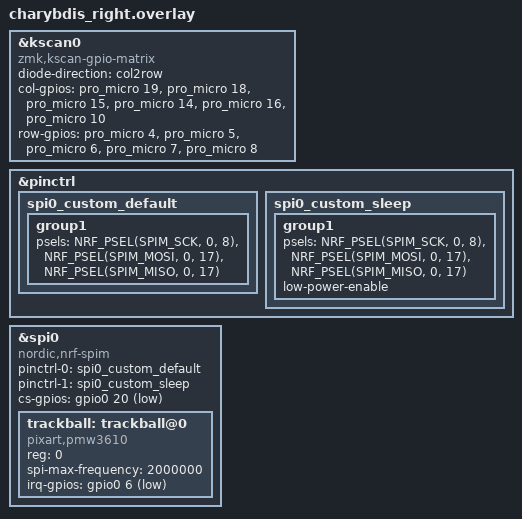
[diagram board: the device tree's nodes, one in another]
#include <dt-bindings/zmk/matrix_transform.h>
#include <dt-bindings/pinctrl/nrf-pinctrl.h>

/* [1] 키 배선 수정 (성공했으니 유지) */
&kscan0 {
    compatible = "zmk,kscan-gpio-matrix";
    diode-direction = "col2row";
    col-gpios
        = <&pro_micro 19 GPIO_ACTIVE_HIGH>
        , <&pro_micro 18 GPIO_ACTIVE_HIGH>
        , <&pro_micro 15 GPIO_ACTIVE_HIGH>
        , <&pro_micro 14 GPIO_ACTIVE_HIGH>
        , <&pro_micro 16 GPIO_ACTIVE_HIGH>
        , <&pro_micro 10 GPIO_ACTIVE_HIGH>;
    row-gpios
        = <&pro_micro 4 (GPIO_ACTIVE_HIGH | GPIO_PULL_DOWN)>
        , <&pro_micro 5 (GPIO_ACTIVE_HIGH | GPIO_PULL_DOWN)>
        , <&pro_micro 6 (GPIO_ACTIVE_HIGH | GPIO_PULL_DOWN)>
        , <&pro_micro 7 (GPIO_ACTIVE_HIGH | GPIO_PULL_DOWN)>
        , <&pro_micro 8 (GPIO_ACTIVE_HIGH | GPIO_PULL_DOWN)>;
};

/* [2] 트랙볼 충돌 방지: 기존 설정을 삭제합니다 */
/delete-node/ &trackball; 

/* [3] 트랙볼 핀 설정 (이름을 Custom으로 변경하여 강제 적용) */
&pinctrl {
    spi0_custom_default: spi0_custom_default {
        group1 {
            psels = <NRF_PSEL(SPIM_SCK, 0, 8)>,
                    <NRF_PSEL(SPIM_MOSI, 0, 17)>,
                    <NRF_PSEL(SPIM_MISO, 0, 17)>;
        };
    };
    spi0_custom_sleep: spi0_custom_sleep {
        group1 {
            psels = <NRF_PSEL(SPIM_SCK, 0, 8)>,
                    <NRF_PSEL(SPIM_MOSI, 0, 17)>,
                    <NRF_PSEL(SPIM_MISO, 0, 17)>;
            low-power-enable;
        };
    };
};

/* [4] SPI 버스에 내 설정 연결 */
&spi0 {
    status = "okay";
    compatible = "nordic,nrf-spim";
    pinctrl-0 = <&spi0_custom_default>; /* 여기를 내 걸로 교체! */
    pinctrl-1 = <&spi0_custom_sleep>;
    pinctrl-names = "default", "sleep";
    cs-gpios = <&gpio0 20 GPIO_ACTIVE_LOW>; /* 표준 CS 핀 */

    trackball: trackball@0 {
        status = "okay";
        compatible = "pixart,pmw3610";
        reg = <0>;
        spi-max-frequency = <2000000>;
        irq-gpios = <&gpio0 6 (GPIO_ACTIVE_LOW | GPIO_PULL_UP)>; /* 표준 IRQ 핀 */
    };
};
